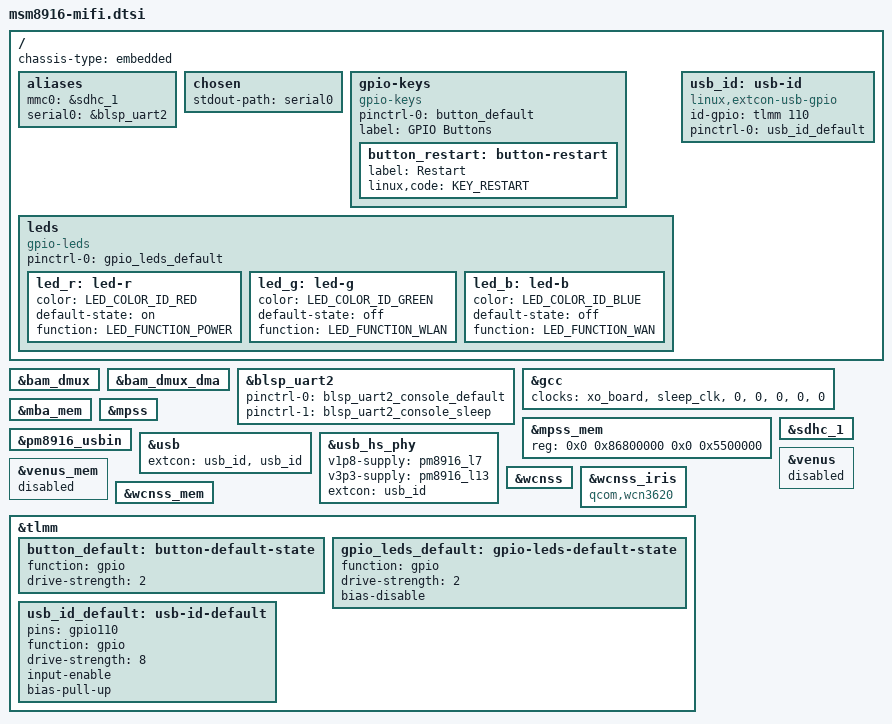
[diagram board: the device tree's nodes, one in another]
// SPDX-License-Identifier: GPL-2.0-only

#include "msm8916-pm8916.dtsi"

#include <dt-bindings/gpio/gpio.h>
#include <dt-bindings/leds/common.h>

/ {
	chassis-type = "embedded";

	aliases {
		mmc0 = &sdhc_1; /* eMMC */
		serial0 = &blsp_uart2;
	};

	chosen {
		stdout-path = "serial0";
	};

	gpio-keys {
		compatible = "gpio-keys";

		pinctrl-0 = <&button_default>;
		pinctrl-names = "default";

		label = "GPIO Buttons";

		/* GPIO is board-specific */
		button_restart: button-restart {
			label = "Restart";
			linux,code = <KEY_RESTART>;
		};
	};

	/*
	 * NOTE: the colour/function pair decides the sysfs name
	 * (<colour>:<function>) that userspace scripts bind to.
	 * /etc/hotplug.d/iface/99-wifi-led expects "green:wlan" and
	 * "blue:wan", so this mapping must stay GREEN=WLAN / BLUE=WAN
	 * (same as msm8916-ufi.dtsi).
	 *
	 * No "heartbeat" trigger on the power LED: it is driven by a
	 * kernel timer that wakes an idle CPU once per second for no
	 * reason on a headless modem stick.
	 */
	leds: leds {
		compatible = "gpio-leds";

		pinctrl-0 = <&gpio_leds_default>;
		pinctrl-names = "default";

		/*
		 * GPIOs are board-specific.
		 * Functions and default-states defined here are fallbacks.
		 * Feel free to override them if your board is different.
		 */
		led_r: led-r {
			color = <LED_COLOR_ID_RED>;
			default-state = "on";
			function = LED_FUNCTION_POWER;
		};

		led_g: led-g {
			color = <LED_COLOR_ID_GREEN>;
			default-state = "off";
			function = LED_FUNCTION_WLAN;
		};

		led_b: led-b {
			color = <LED_COLOR_ID_BLUE>;
			default-state = "off";
			function = LED_FUNCTION_WAN;
		};
	};

	usb_id: usb-id {
		compatible = "linux,extcon-usb-gpio";
		id-gpio = <&tlmm 110 GPIO_ACTIVE_HIGH>;
		pinctrl-names = "default";
		pinctrl-0 = <&usb_id_default>;
	};
};

&bam_dmux {
	status = "okay";
};

&bam_dmux_dma {
	status = "okay";
};

/*
 * FIX: the console UART needs its pads muxed.
 * msm8916-ufi.dtsi sets blsp_uart2_console_default / _sleep here; this file
 * only did "status = okay", which leaves gpio4/gpio5 unconfigured while the
 * kernel console (console=ttyMSM0,115200) is still attached to the port.
 * Unmuxed pads let the RX line float, which produces line-noise framing
 * errors that the tty layer turns into a steady stream of interrupts and
 * console output - pure overhead on a box whose only job is forwarding
 * packets. Mux the pins properly (as ufi.dtsi does).
 */
&blsp_uart2 {
	pinctrl-0 = <&blsp_uart2_console_default>;
	pinctrl-1 = <&blsp_uart2_console_sleep>;
	pinctrl-names = "default", "sleep";
	status = "okay";
};

/* Remove &dsi_phy0 from clocks to make sure that gcc probes with display disabled */
&gcc {
	clocks = <&xo_board>, <&sleep_clk>, <0>, <0>, <0>, <0>, <0>;
};

&mba_mem {
	status = "okay";
};

&mpss {
	status = "okay";
};

&mpss_mem {
	reg = <0x0 0x86800000 0x0 0x5500000>;
	status = "okay";
};

&pm8916_usbin {
	status = "okay";
};

&sdhc_1 {
	status = "okay";
};

&usb {
	status = "okay";
	extcon = <&usb_id>, <&usb_id>;
};

&usb_hs_phy {
	v1p8-supply = <&pm8916_l7>;
	v3p3-supply = <&pm8916_l13>;
	extcon = <&usb_id>;
};

/*
 * Venus is the video encode/decode core. This board is a headless 4G modem
 * stick - there is no camera and no display, so enabling it only costs us
 * 5 MB of reserved memory (venus_mem) plus permanently-on clocks and
 * power/interconnect votes. Disabled.
 */
&venus {
	status = "disabled";
};

&venus_mem {
	status = "disabled";
};

&wcnss {
	status = "okay";
};

&wcnss_iris {
	compatible = "qcom,wcn3620";
};

&wcnss_mem {
	status = "okay";
};

&tlmm {
	/* pins are board-specific */
	button_default: button-default-state {
		function = "gpio";
		drive-strength = <2>;
	};

	gpio_leds_default: gpio-leds-default-state {
		function = "gpio";
		drive-strength = <2>;
		bias-disable;
	};

	usb_id_default: usb-id-default {
		pins = "gpio110";
		function = "gpio";

		drive-strength = <8>;
		input-enable;
		bias-pull-up;
	};
};
